# K1921VK028 register map
Vendor: NIIET; Series: K1921VKx; File version: 2.17
CPU: CM4 r0p1, little endian, MPU, FPU, 4 interrupt priority bits
Registers are 32-bit, read-write, reset 0x0 unless marked. A register's access mark holds for its fields unless they carry their own. Offsets are from the block's base; [hi:lo] are bit positions.

## MILSTD0 — MIL-STD 1553 control registers
Base 0x40072000
Same registers: MILSTD1 0x40073000
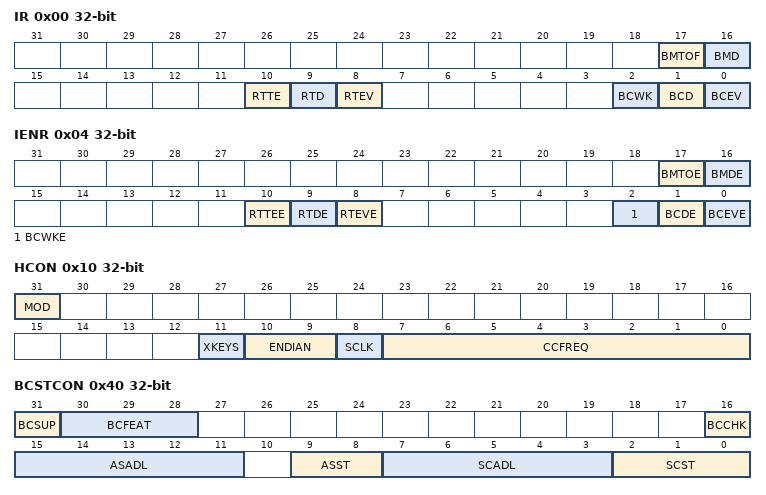
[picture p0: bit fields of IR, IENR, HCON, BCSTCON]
0x00 IR — BSI interrupt register
  [17] BMTOF — BM timer overflow
  [16] BMD — BM DMA error
  [10] RTTE — RT table access error
  [9] RTD — RT DMA error
  [8] RTEV — RT transfer event interrupt
  [2] BCWK — BC timer interrupt
  [1] BCD — BC DMA error
  [0] BCEV — BC transfer event interrupt
0x04 IENR — BSI interrupt enable register
  [17] BMTOE — BMTOF interrupt enable
  [16] BMDE — BMD interrupt enable
  [10] RTTEE — RTTE interrupt enable
  [9] RTDE — RTD interrupt enable
  [8] RTEVE — RTEV interrupt enable
  [2] BCWKE — BCWK interrupt enable
  [1] BCDE — BCD interrupt enable
  [0] BCEVE — BCEVE interrupt enable
0x10 HCON ro — BSI hardware configuration register
  [31] MOD — Modified
  [11] XKEYS — Enable safety keys
  [10:9] ENDIAN — AHB Endianness
  [8] SCLK — Same clock
  [7:0] CCFREQ — Codec clock frequency
0x40 BCSTCON — BC status and config register
  [31] BCSUP — BC supported
  [30:28] BCFEAT — BC features
  [16] BCCHK — Check broadcast
  [15:11] ASADL — Asynchronous list address low bits
  [9:8] ASST — Asynchronous list state
  [7:3] SCADL — Schedule address low bits
  [2:0] SCST — Schedule state
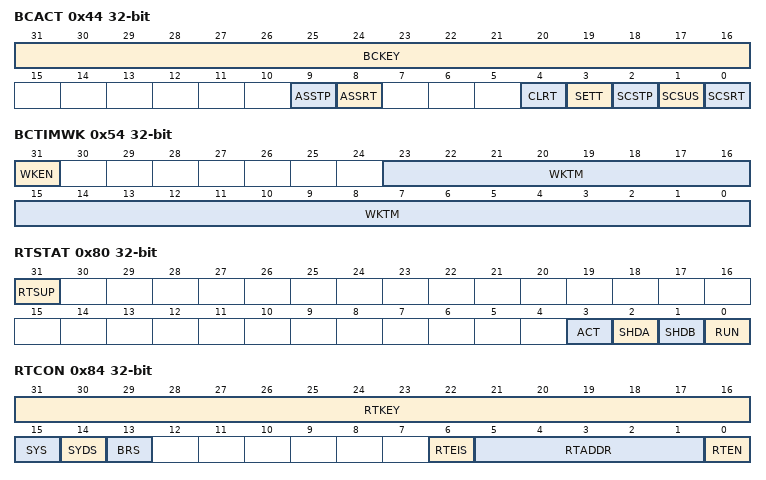
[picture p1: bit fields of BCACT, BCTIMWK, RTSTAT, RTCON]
0x44 BCACT wo — BC action register
  [31:16] BCKEY — BC safety code
    on write: 0x1552=Code (BC safety code)
  [9] ASSTP — Asynchronous list stop
  [8] ASSRT — Asynchronous list start
  [4] CLRT — Clear external trigger
  [3] SETT — Set external trigger
  [2] SCSTP — Schedule stop
  [1] SCSUS — Schedule suspend
  [0] SCSRT — Schedule start
0x48 BCLNP — BC transfer list next pointer
  [31:0] SCTLP — Schedule transfer list pointer
0x4C BCALNP — BC asynchronous list next pointer register
  [31:0] ASLP — Asynchronous list pointer
0x50 BCTIM ro — BC timer register
  [23:0] SCTM — Schedule time
0x54 BCTIMWK — BC timer wake-up register
  [31] WKEN — Wake-up timer enable
  [23:0] WKTM — Wake-up time
0x58 BCTRP — BC transfer-triggered IRQ ring position register
  [31:0] SPRP — BC IRQ source pointer ring position
0x5C BCBSW — BC per-RT bus swap register
  [31:0] BPRBS — BC per-RT bus swap
0x68 BCTSP ro — BC transfer list current slot pointer
  [31:0] TSP — BC transfer slot pointer
0x6C BCATSP ro — BC asynchronous list current slot pointer
  [31:0] ATSP — BC asynchronous transfer slot pointer
0x80 RTSTAT ro — RT status register
  [31] RTSUP — RT supported
  [3] ACT — RT active
  [2] SHDA — Bus A shutdown
  [1] SHDB — Bus B shutdown
  [0] RUN — RT running
0x84 RTCON — RT config register
  [31:16] RTKEY — RT safety code
    0x1553=Code (RT safety code)
  [15] SYS — Sync enable
  [14] SYDS — Sync with data enable
  [13] BRS — Bus reset enable
  [6] RTEIS — external RT address set
  [5:1] RTADDR — RT address
  [0] RTEN — RT enable
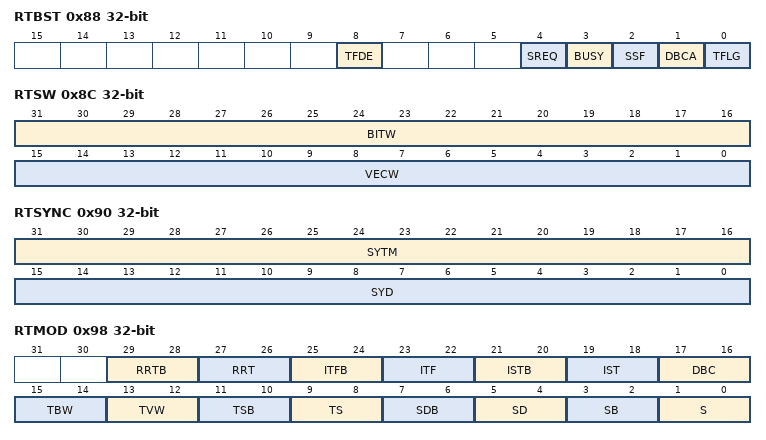
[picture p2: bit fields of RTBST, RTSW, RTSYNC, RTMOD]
0x88 RTBST — RT bus status register
  [8] TFDE — Set terminal flag
  [4] SREQ — Service request
  [3] BUSY — Busy bit
  [2] SSF — Subsystem flag
  [1] DBCA — Dynamic BC acceptance
  [0] TFLG — Terminal flag
0x8C RTSW — RT status words register
  [31:16] BITW — BIT Word
  [15:0] VECW — Vector word
0x90 RTSYNC ro
  [31:16] SYTM — RT sync time
  [15:0] SYD — RT sync data
0x94 RTSADDR — RT subaddress table base address
  [31:9] SATB — RT subaddress table base
0x98 RTMOD — RT mode control register
  [29:28] RRTB — reset RT broadcast
  [27:26] RRT — Reset RT
  [25:24] ITFB — Inhibit terminal flag broadcast
  [23:22] ITF — Inhibit terminal flag
  [21:20] ISTB — Initiate self test broadcast
  [19:18] IST — Initiate self test
  [17:16] DBC — Dynamic bus control
  [15:14] TBW — Transmit BIT word
  [13:12] TVW — Transmit vector word
  [11:10] TSB — Transmitter shutdown broadcast
  [9:8] TS — Transmitter shutdown
  [7:6] SDB — Synchronize with data word broadcast
  [5:4] SD — Synchronize with data word
  [3:2] SB — Synchronize broadcast
  [1:0] S — Syncronize
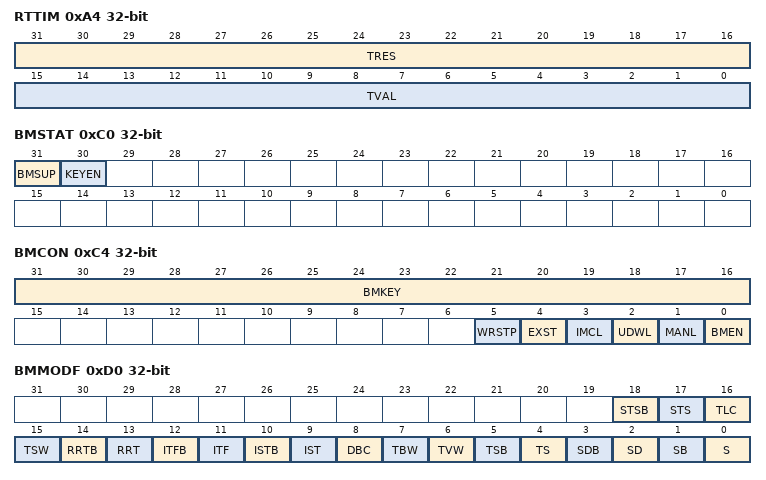
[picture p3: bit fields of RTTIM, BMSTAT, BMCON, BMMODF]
0xA4 RTTIM — RT time tag control register
  [31:16] TRES — Time tag resolution
  [15:0] TVAL — Time tag value
0xAC RTELMSK — RT event log mask register
  [20:2] ELSM — Event log size mask
0xB0 RTELP — RT event log position pointer
  [31:0] ELWP — Event log write pointer
0xB4 RTELIP ro — RT event log interrupt position register
  [31:0] ELIP — Event log irq pointer
0xC0 BMSTAT ro — BM status register
  [31] BMSUP — BM supported
  [30] KEYEN — Key enabled
0xC4 BMCON — BM control register
  [31:16] BMKEY — Safety key
    0x1554=Code (BM safety code)
  [5] WRSTP — Wrap stop
  [4] EXST — External sync start
  [3] IMCL — Invalid mode code log
  [2] UDWL — Unexpected data word log
  [1] MANL — Manchester parity error log
  [0] BMEN — BM enable
0xC8 BMADF — BM RT address filter register
  [31:0] AFM — Address filter mask
0xCC BMSADF — BM RT subaddress filter register
  [31:0] SAFM — Subaddress filter mask
0xD0 BMMODF — BM RT mode code filter register
  [18] STSB — Selected transmitter shutdown broadcast
  [17] STS — Selected transmitter shutdown
  [16] TLC — Transmit last command
  [15] TSW — Transmit status word
  [14] RRTB — Reset RT broadcast
  [13] RRT — Reset RT
  [12] ITFB — Inhibit termital flag broadcast
  [11] ITF — Inhibit terminal flag
  [10] ISTB — Initiate self test broadcast
  [9] IST — Initiate self test
  [8] DBC — Dynamic bus control
  [7] TBW — Transmit BIT word
  [6] TVW — Transmit vector word
  [5] TSB — Transmitter shutdown broadcast
  [4] TS — Transmitter shutdown
  [3] SDB — Syncronize with data word broadcast
  [2] SD — Syncronize with data word
  [1] SB — Syncronize broadcast
  [0] S — Syncronize
0xD4 BMLBS — BM log buffer start
  [31:0] BMBS
0xD8 BMLBE — BM log buffer end
  [21:0] BMBE
0xDC BMLBP — BM log buffer position
  [21:0] BMBP
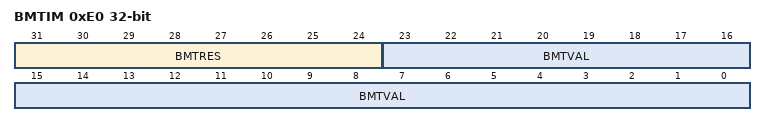
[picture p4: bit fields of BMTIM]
0xE0 BMTIM — BM time tag control register
  [31:24] BMTRES — Time tag resolution
  [23:0] BMTVAL — Time tag value
